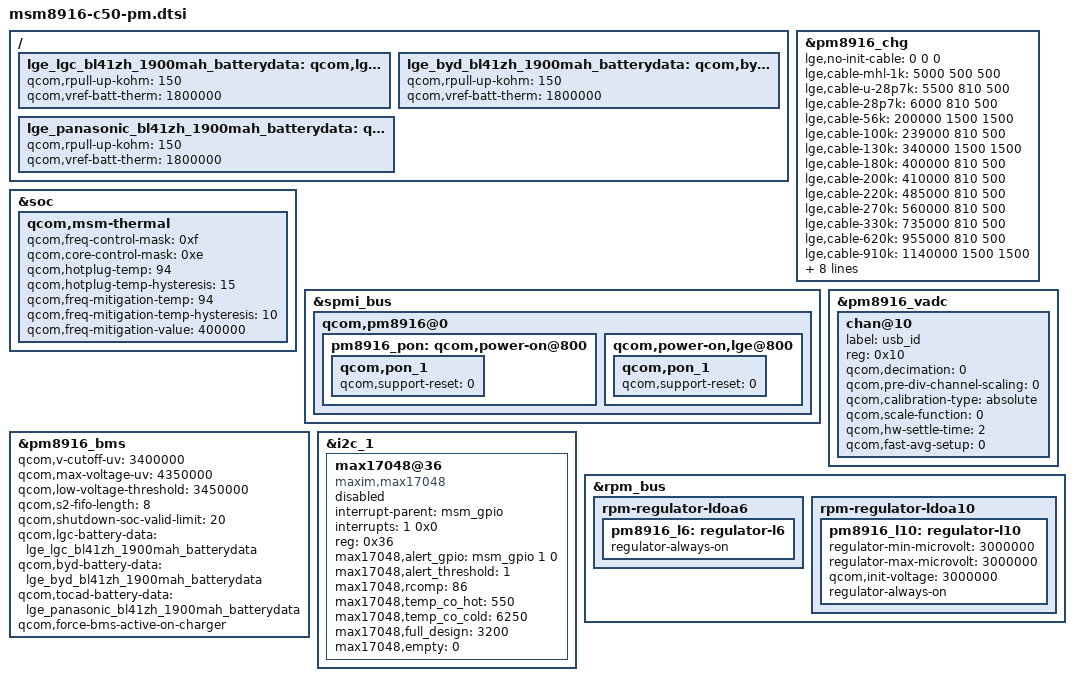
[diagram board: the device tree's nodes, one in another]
/* Copyright (c) 2012, Code Aurora Forum. All rights reserved.
 *
 * This program is free software; you can redistribute it and/or modify
* it under the terms of the GNU General Public License version 2 and
* only version 2 as published by the Free Software Foundation.
*
* This program is distributed in the hope that it will be useful,
* but WITHOUT ANY WARRANTY; without even the implied warranty of
* MERCHANTABILITY or FITNESS FOR A PARTICULAR PURPOSE.  See the
* GNU General Public License for more details.
*/

&pm8916_chg {
	status = "ok";

	lge,no-init-cable = <0 0 0>;
	lge,cable-mhl-1k = <5000 500 500>;
	lge,cable-u-28p7k = <5500 810 500>;
	lge,cable-28p7k = <6000 810 500>;
	lge,cable-56k = <200000 1500 1500>;
	lge,cable-100k = <239000 810 500>;
	lge,cable-130k = <340000 1500 1500>;
	lge,cable-180k = <400000 810 500>;
	lge,cable-200k = <410000 810 500>;
	lge,cable-220k = <485000 810 500>;
	lge,cable-270k = <560000 810 500>;
	lge,cable-330k = <735000 810 500>;
	lge,cable-620k = <955000 810 500>;
	lge,cable-910k = <1140000 1500 1500>;
	lge,cable-none = <1900000 810  500>;

	qcom,vddmax-mv = <4350>;
	qcom,vddsafe-mv = <4380>;
	qcom,vinmin-mv = <4470>;
	qcom,tchg-mins = <480>;
	qcom,btc-disabled;
	qcom,resume-soc = <97>;
	qcom,disable-vbatdet-based-recharge;
};

&soc {
	qcom,msm-thermal {
		qcom,freq-control-mask = <0xf>;
		qcom,core-control-mask = <0xe>;
		qcom,hotplug-temp = <94>;
		qcom,hotplug-temp-hysteresis = <15>;
		qcom,freq-mitigation-temp = <94>;
		qcom,freq-mitigation-temp-hysteresis = <10>;
		qcom,freq-mitigation-value = <400000>;
		};
};

&spmi_bus {
qcom,pm8916@0 {
	pm8916_pon: qcom,power-on@800 {
			qcom,pon_1 {
				qcom,support-reset = <0>;
			};
		};
	qcom,power-on,lge@800{
			 qcom,pon_1 {
				qcom,support-reset = <0>;
			};
		};
	};
};

/ {
	lge_lgc_bl41zh_1900mah_batterydata: qcom,lgc-battery-data {
		qcom,rpull-up-kohm = <150>;
		qcom,vref-batt-therm = <1800000>;
		#include "../msm8916-lge-common/batterydata_LGE_lgc_1900mAh.dtsi"
	};
	lge_byd_bl41zh_1900mah_batterydata: qcom,byd-battery-data {
		qcom,rpull-up-kohm = <150>;
		qcom,vref-batt-therm = <1800000>;
		#include "../msm8916-lge-common/batterydata_LGE_byd_1900mAh.dtsi"
        };
	lge_panasonic_bl41zh_1900mah_batterydata: qcom,tocad-battery-data {
		qcom,rpull-up-kohm = <150>;
		qcom,vref-batt-therm = <1800000>;
		#include "../msm8916-lge-common/batterydata_LGE_panasonic_1900mAh.dtsi"
        };
};

&pm8916_bms {
	status = "ok";
	qcom,v-cutoff-uv = <3400000>;
	qcom,max-voltage-uv = <4350000>;
	qcom,low-voltage-threshold = <3450000>;
	qcom,s2-fifo-length = <8>;
	qcom,shutdown-soc-valid-limit = <20>;
	qcom,lgc-battery-data = <&lge_lgc_bl41zh_1900mah_batterydata>;
	qcom,byd-battery-data = <&lge_byd_bl41zh_1900mah_batterydata>;
	qcom,tocad-battery-data = <&lge_panasonic_bl41zh_1900mah_batterydata>;
	qcom,force-bms-active-on-charger;
};

&pm8916_vadc {
	chan@10 {
		label = "usb_id";
		reg = <0x10>;
		qcom,decimation = <0>;
		qcom,pre-div-channel-scaling = <0>;
		qcom,calibration-type = "absolute";
		qcom,scale-function = <0>;
		qcom,hw-settle-time = <2>;
		qcom,fast-avg-setup = <0>;
	};
};

&i2c_1 {
	max17048@36 {
		compatible = "maxim,max17048";
		status = "disabled";
		interrupt-parent = <&msm_gpio>;
		interrupts = <1 0x0>;
		reg = <0x36>;
		max17048,alert_gpio = <&msm_gpio 1 0>;
		max17048,alert_threshold = <1>;
		max17048,rcomp = <86>;
		max17048,temp_co_hot = <550>;
		max17048,temp_co_cold = <6250>;
		max17048,full_design = <3200>;
		max17048,empty = <0>;     /* 3.4 Cut-off 0.0%  */
	};
};

&rpm_bus {
	rpm-regulator-ldoa6 {
		status = "okay";
		pm8916_l6: regulator-l6 {
			regulator-always-on;
			status = "okay";
		};
	};

	rpm-regulator-ldoa10 {
		status = "okay";
		pm8916_l10: regulator-l10 {
			regulator-min-microvolt = <3000000>;
			regulator-max-microvolt = <3000000>;
			qcom,init-voltage = <3000000>;
			regulator-always-on;
			status = "okay";
		};
	};
};
